VERSION ""

NS_ :

BS_:

BU_: ElconCharger BMS

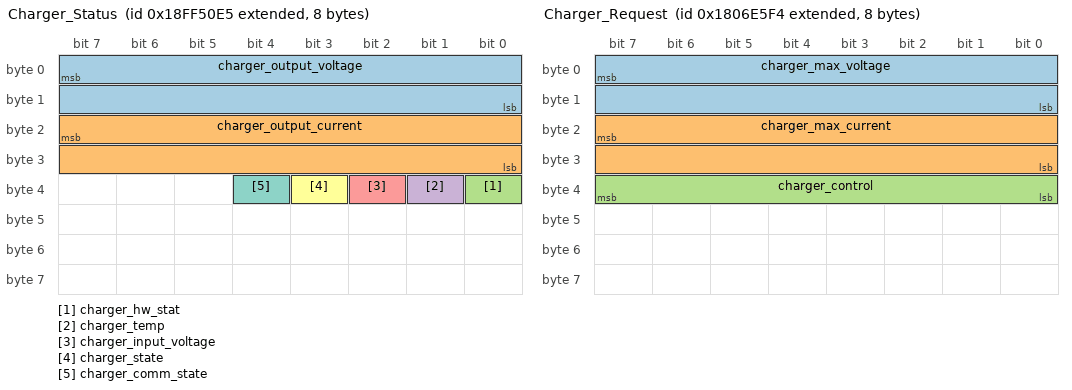
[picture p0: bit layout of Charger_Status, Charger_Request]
BO_ 2566869221 Charger_Status: 8 ElconCharger
 SG_ charger_output_voltage : 7|16@0+ (0.1,0) [0|0] "V" Vector__XXX
 SG_ charger_output_current : 23|16@0+ (0.1,0) [0|0] "A" Vector__XXX
 SG_ charger_hw_stat : 32|1@1+ (1,0) [0|0] "flag" Vector__XXX
 SG_ charger_temp : 33|1@1+ (1,0) [0|0] "flag" Vector__XXX
 SG_ charger_input_voltage : 34|1@1+ (1,0) [0|0] "flag" Vector__XXX
 SG_ charger_state : 35|1@1+ (1,0) [0|0] "flag" Vector__XXX
 SG_ charger_comm_state : 36|1@1+ (1,0) [0|0] "flag" Vector__XXX

BO_ 2550588916 Charger_Request: 8 BMS
 SG_ charger_max_voltage : 7|16@0+ (0.1,0) [0|0] "V" Vector__XXX
 SG_ charger_max_current : 23|16@0+ (0.1,0) [0|0] "A" Vector__XXX
 SG_ charger_control : 32|8@1+ (1,0) [0|0] "" Vector__XXX

CM_ SG_ 2566869221 charger_output_voltage "Output Voltage";
CM_ SG_ 2566869221 charger_output_current "Output Current";
CM_ SG_ 2566869221 charger_hw_stat "Charger status";
CM_ SG_ 2566869221 charger_temp "Charger temperature";
CM_ SG_ 2566869221 charger_input_voltage "Charger input voltage";
CM_ SG_ 2566869221 charger_state "Charger starting state";
CM_ SG_ 2566869221 charger_comm_state "Charger communication state";
CM_ SG_ 2550588916 charger_max_voltage "Max Allowable Charging Terminal Voltage";
CM_ SG_ 2550588916 charger_max_current "Max Allowable Charging Current";
CM_ SG_ 2550588916 charger_control "Toggle charging";
BA_DEF_ BO_  "GenMsgCycleTime" INT 2 50000;
BA_DEF_DEF_  "GenMsgCycleTime" 100;
BA_ "GenMsgCycleTime" BO_ 2566869221 1000;
BA_ "GenMsgCycleTime" BO_ 2550588916 1000;
VAL_ 2566869221 charger_hw_stat 0 "HW_STATUS_OK" 1 "HW_STATUS_FAIL" ;
VAL_ 2566869221 charger_temp 0 "TEMP_OK" 1 "TEMP_FAULT" ;
VAL_ 2566869221 charger_input_voltage 0 "INPUT_VOLTAGE_OK" 1 "INPUT_VOLTAGE_FAULT" ;
VAL_ 2566869221 charger_state 0 "STATE_CHARGING" 1 "STATE_OFF" ;
VAL_ 2566869221 charger_comm_state 0 "COMM_STATE_OK" 1 "COMM_STATE_TIMEOUT" ;
VAL_ 2550588916 charger_control 1 "CHARGING_STOP" 0 "CHARGING_START" ;
